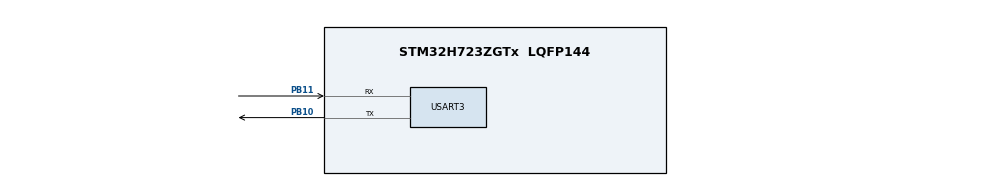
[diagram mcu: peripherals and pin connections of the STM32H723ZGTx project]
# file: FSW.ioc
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CORTEX_M7.CPU_DCache=Enabled
CORTEX_M7.CPU_ICache=Enabled
CORTEX_M7.MPU_Control=__NULL
CORTEX_M7.default_mode_Activation=0
FREERTOS.Tasks01=defaultTask,24,128,StartDefaultTask,Default,NULL,Dynamic,NULL,NULL
FREERTOS.configTOTAL_HEAP_SIZE=50000
FREERTOS.configUSE_NEWLIB_REENTRANT=1
IWDG1.Prescaler=IWDG_PRESCALER_32
IWDG1.Window=3999
Mcu.Family=STM32H7
Mcu.Name=STM32H723ZGTx
Mcu.Package=LQFP144
NVIC.PriorityGroup=NVIC_PRIORITYGROUP_4
NVIC.TIM6_DAC_IRQn=true\:15\:0\:false\:false\:true\:false\:false\:true\:true
NVIC.TimeBase=TIM6_DAC_IRQn
NVIC.TimeBaseIP=TIM6
PB10.Mode=Asynchronous
PB10.Signal=USART3_TX
PB11.Mode=Asynchronous
PB11.Signal=USART3_RX
PH0-OSC_IN.Mode=HSE-External-Clock-Source
PH0-OSC_IN.Signal=RCC_OSC_IN
ProjectManager.HeapSize=0x200
ProjectManager.StackSize=0x400
ProjectManager.TargetToolchain=STM32CubeIDE
RCC.ADCFreq_Value=76000000
RCC.APB1Freq_Value=120000000
RCC.APB2Freq_Value=120000000
RCC.APB3Freq_Value=120000000
RCC.APB4Freq_Value=120000000
RCC.CortexFreq_Value=480000000
RCC.D1PPRE=RCC_APB3_DIV2
RCC.D2PPRE1=RCC_APB1_DIV2
RCC.D2PPRE2=RCC_APB2_DIV2
RCC.D3PPRE=RCC_APB4_DIV2
RCC.DIVM1=1
RCC.DIVM2=1
RCC.DIVN1=60
RCC.DIVN2=19
RCC.DIVP1=1
RCC.DIVQ1=4
RCC.EnbaleCSS=true
RCC.HCLKFreq_Value=240000000
RCC.HPRE=RCC_HCLK_DIV2
RCC.HSE_VALUE=8000000
RCC.PLL2FRACN=0
RCC.PLL3FRACN=0
RCC.PLLFRACN=0
RCC.PLLSourceVirtual=RCC_PLLSOURCE_HSE
RCC.SYSCLKFreq_VALUE=480000000
RCC.SYSCLKSource=RCC_SYSCLKSOURCE_PLLCLK
RCC.USBCLockSelection=RCC_USBCLKSOURCE_HSI48
RCC.USBFreq_Value=48000000
STMicroelectronics.FP-SNS-STAIOTCFT.1.1.0.MathOoLibCcCMSISJjDSPJjInclude=true
STMicroelectronics.FP-SNS-STAIOTCFT.1.1.0.MathOoLibCcCMSISJjDSPJjLib=true
STMicroelectronics.X-CUBE-ALGOBUILD.1.4.0.LibraryCcDSPOoLibraryJjDSPOoLibrary=true
USART3.VirtualMode-Asynchronous=VM_ASYNC
VP_FREERTOS_VS_CMSIS_V2.Mode=CMSIS_V2
VP_IWDG1_VS_IWDG.Mode=IWDG_Activate
VP_MEMORYMAP_VS_MEMORYMAP.Mode=CurAppReg
VP_STMicroelectronics.FP-SNS-STAIOTCFT_VS_CMSISJjMathOoLib_1.0.0_1.1.0.Mode=CMSISJjMathOoLib
VP_STMicroelectronics.X-CUBE-ALGOBUILD_VS_DSPOoLibraryJjLibrary_1.4.0_1.4.0.Mode=DSPOoLibraryJjLibrary
VP_SYS_VS_tim6.Mode=TIM6
board=NUCLEO-H723ZG

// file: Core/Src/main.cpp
/* USER CODE BEGIN Header */
/**
  ******************************************************************************
  * @file           : main.c
  * @brief          : Main program body
  ******************************************************************************
  * @attention
  *
  * Copyright (c) 2026 STMicroelectronics.
  * All rights reserved.
  *
  * This software is licensed under terms that can be found in the LICENSE file
  * in the root directory of this software component.
  * If no LICENSE file comes with this software, it is provided AS-IS.
  *
  ******************************************************************************
  */
/* USER CODE END Header */
#include "main.h"
#include "FreeRTOS.h"
#include "cmsis_os2.h"
#include "iwdg.h"
#include "usart.h"
#include "gpio.h"

void SystemClock_Config(void);
void MX_FREERTOS_Init(void);

int main(void)
{

  /* Enable the CPU Cache */

  /* Enable I-Cache---------------------------------------------------------*/
  SCB_EnableICache();

  /* Enable D-Cache---------------------------------------------------------*/
  SCB_EnableDCache();

  /* MCU Configuration--------------------------------------------------------*/

  /* Reset of all peripherals, Initializes the Flash interface and the Systick. */
  HAL_Init();

  /* USER CODE BEGIN Init */
//#if defined(DEBUG)
//  __HAL_DBGMCU_FREEZE_IWDG1();
//#endif

  /* USER CODE END Init */

  /* Configure the system clock */
  SystemClock_Config();

  /* Initialize all configured peripherals */
  MX_GPIO_Init();
  MX_USART3_UART_Init();
  MX_IWDG1_Init();

  /* Init scheduler */
  osKernelInitialize();  /* Call init function for freertos objects (in cmsis_os2.c) */
  MX_FREERTOS_Init();

  /* Start scheduler */
  osKernelStart();

  /* We should never get here as control is now taken by the scheduler */

  /* Infinite loop */
  while (1)
  {

  }
}

void SystemClock_Config(void)
{
  RCC_OscInitTypeDef RCC_OscInitStruct = {0};
  RCC_ClkInitTypeDef RCC_ClkInitStruct = {0};

  /** Supply configuration update enable
  */
  HAL_PWREx_ConfigSupply(PWR_LDO_SUPPLY);

  /** Configure the main internal regulator output voltage
  */
  __HAL_PWR_VOLTAGESCALING_CONFIG(PWR_REGULATOR_VOLTAGE_SCALE0);

  while(!__HAL_PWR_GET_FLAG(PWR_FLAG_VOSRDY)) {}

  /** Initializes the RCC Oscillators according to the specified parameters
  * in the RCC_OscInitTypeDef structure.
  */
  RCC_OscInitStruct.OscillatorType = RCC_OSCILLATORTYPE_LSI|RCC_OSCILLATORTYPE_HSE;
  RCC_OscInitStruct.HSEState = RCC_HSE_BYPASS;
  RCC_OscInitStruct.LSIState = RCC_LSI_ON;
  RCC_OscInitStruct.PLL.PLLState = RCC_PLL_ON;
  RCC_OscInitStruct.PLL.PLLSource = RCC_PLLSOURCE_HSE;
  RCC_OscInitStruct.PLL.PLLM = 1;
  RCC_OscInitStruct.PLL.PLLN = 60;
  RCC_OscInitStruct.PLL.PLLP = 1;
  RCC_OscInitStruct.PLL.PLLQ = 4;
  RCC_OscInitStruct.PLL.PLLR = 2;
  RCC_OscInitStruct.PLL.PLLRGE = RCC_PLL1VCIRANGE_3;
  RCC_OscInitStruct.PLL.PLLVCOSEL = RCC_PLL1VCOWIDE;
  RCC_OscInitStruct.PLL.PLLFRACN = 0;
  if (HAL_RCC_OscConfig(&RCC_OscInitStruct) != HAL_OK)
  {
    Error_Handler();
  }

  /** Initializes the CPU, AHB and APB buses clocks
  */
  RCC_ClkInitStruct.ClockType = RCC_CLOCKTYPE_HCLK|RCC_CLOCKTYPE_SYSCLK
                              |RCC_CLOCKTYPE_PCLK1|RCC_CLOCKTYPE_PCLK2
                              |RCC_CLOCKTYPE_D3PCLK1|RCC_CLOCKTYPE_D1PCLK1;
  RCC_ClkInitStruct.SYSCLKSource = RCC_SYSCLKSOURCE_PLLCLK;
  RCC_ClkInitStruct.SYSCLKDivider = RCC_SYSCLK_DIV1;
  RCC_ClkInitStruct.AHBCLKDivider = RCC_HCLK_DIV2;
  RCC_ClkInitStruct.APB3CLKDivider = RCC_APB3_DIV2;
  RCC_ClkInitStruct.APB1CLKDivider = RCC_APB1_DIV2;
  RCC_ClkInitStruct.APB2CLKDivider = RCC_APB2_DIV2;
  RCC_ClkInitStruct.APB4CLKDivider = RCC_APB4_DIV2;

  if (HAL_RCC_ClockConfig(&RCC_ClkInitStruct, FLASH_LATENCY_3) != HAL_OK)
  {
    Error_Handler();
  }

  /** Enables the Clock Security System
  */
  HAL_RCC_EnableCSS();
}

void HAL_TIM_PeriodElapsedCallback(TIM_HandleTypeDef *htim)
{
  if (htim->Instance == TIM6)
  {
    HAL_IncTick();
  }
}

void Error_Handler(void)
{
  __disable_irq();
  while (1)
  {
  }
}
